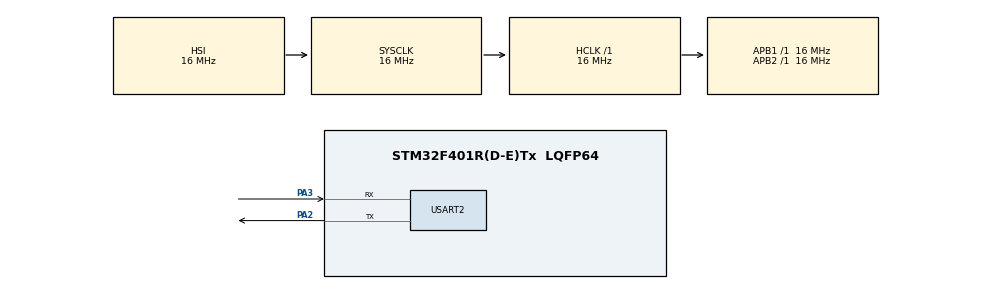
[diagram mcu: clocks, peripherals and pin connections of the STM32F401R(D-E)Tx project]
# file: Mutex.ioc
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FREERTOS.Tasks01=defaultTask,0,128,StartDefaultTask,Default,NULL,Dynamic,NULL,NULL
Mcu.Family=STM32F4
Mcu.Name=STM32F401R(D-E)Tx
Mcu.Package=LQFP64
NVIC.PriorityGroup=NVIC_PRIORITYGROUP_4
NVIC.RCC_IRQn=true\:5\:0\:false\:false\:true\:true\:true\:false\:true
NVIC.TIM1_UP_TIM10_IRQn=true\:15\:0\:false\:false\:true\:false\:false\:true\:true
NVIC.TimeBase=TIM1_UP_TIM10_IRQn
NVIC.TimeBaseIP=TIM1
NVIC.USART2_IRQn=true\:5\:0\:false\:false\:true\:true\:true\:true\:true
PA2.Mode=Asynchronous
PA2.Signal=USART2_TX
PA3.Mode=Asynchronous
PA3.Signal=USART2_RX
PH0\ -\ OSC_IN.Mode=HSE-External-Oscillator
PH0\ -\ OSC_IN.Signal=RCC_OSC_IN
PH1\ -\ OSC_OUT.Mode=HSE-External-Oscillator
PH1\ -\ OSC_OUT.Signal=RCC_OSC_OUT
ProjectManager.HeapSize=0x200
ProjectManager.StackSize=0x400
ProjectManager.TargetToolchain=STM32CubeIDE
RCC.AHBFreq_Value=16000000
RCC.APB1Freq_Value=16000000
RCC.APB2Freq_Value=16000000
RCC.CortexFreq_Value=16000000
RCC.HSE_VALUE=25000000
RCC.HSI_VALUE=16000000
RCC.LSE_VALUE=32768
RCC.SYSCLKFreq_VALUE=16000000
RCC.VCOOutputFreq_Value=192000000
USART2.VirtualMode=VM_ASYNC
VP_FREERTOS_VS_CMSIS_V1.Mode=CMSIS_V1
VP_SYS_VS_tim1.Mode=TIM1
board=custom

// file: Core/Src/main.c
/* USER CODE BEGIN Header */
/**
  ******************************************************************************
  * @file           : main.c
  * @brief          : Main program body
  ******************************************************************************
  * @attention
  *
  * Copyright (c) 2025 STMicroelectronics.
  * All rights reserved.
  *
  * This software is licensed under terms that can be found in the LICENSE file
  * in the root directory of this software component.
  * If no LICENSE file comes with this software, it is provided AS-IS.
  *
  ******************************************************************************
  */
/* USER CODE END Header */
#include "main.h"
#include "cmsis_os.h"

UART_HandleTypeDef huart2;

void SystemClock_Config(void);
static void MX_GPIO_Init(void);
static void MX_USART2_UART_Init(void);

SemaphoreHandle_t SimpleMutex;
TaskHandle_t HPT_Handler;
TaskHandle_t MPT_Handler;
void HPT_Task (void *argument);
void MPT_Task (void *argument);
void Send_Uart (uint8_t *str)
{
xSemaphoreTake(SimpleMutex, portMAX_DELAY);
HAL_Delay(2000);
HAL_UART_Transmit(&huart2, str, strlen (str), HAL_MAX_DELAY);
xSemaphoreGive(SimpleMutex);
}

int main(void)
{

  /* MCU Configuration--------------------------------------------------------*/

  /* Reset of all peripherals, Initializes the Flash interface and the Systick. */
  HAL_Init();

  /* Configure the system clock */
  SystemClock_Config();

  /* Initialize all configured peripherals */
  MX_GPIO_Init();
  MX_USART2_UART_Init();

  /* USER CODE BEGIN RTOS_MUTEX */
  SimpleMutex = xSemaphoreCreateMutex();
  if (SimpleMutex != NULL)
  {
  HAL_UART_Transmit(&huart2, "Mutex Created\n\n", 15, 1000);
  }
  /// create tasks
  xTaskCreate(HPT_Task, "HPT", 128, NULL, 3, &HPT_Handler);
  xTaskCreate(MPT_Task, "MPT", 128, NULL, 2, &MPT_Handler);
  vTaskStartScheduler();
  /* start timers, add new ones, ... */
  /* USER CODE END RTOS_TIMERS */

  /* Start scheduler */
  osKernelStart();

  /* We should never get here as control is now taken by the scheduler */

  /* Infinite loop */
  while (1)
  {

  }
}

void SystemClock_Config(void)
{
  RCC_OscInitTypeDef RCC_OscInitStruct = {0};
  RCC_ClkInitTypeDef RCC_ClkInitStruct = {0};

  /** Configure the main internal regulator output voltage
  */
  __HAL_RCC_PWR_CLK_ENABLE();
  __HAL_PWR_VOLTAGESCALING_CONFIG(PWR_REGULATOR_VOLTAGE_SCALE2);

  /** Initializes the RCC Oscillators according to the specified parameters
  * in the RCC_OscInitTypeDef structure.
  */
  RCC_OscInitStruct.OscillatorType = RCC_OSCILLATORTYPE_HSI;
  RCC_OscInitStruct.HSIState = RCC_HSI_ON;
  RCC_OscInitStruct.HSICalibrationValue = RCC_HSICALIBRATION_DEFAULT;
  RCC_OscInitStruct.PLL.PLLState = RCC_PLL_NONE;
  if (HAL_RCC_OscConfig(&RCC_OscInitStruct) != HAL_OK)
  {
    Error_Handler();
  }

  /** Initializes the CPU, AHB and APB buses clocks
  */
  RCC_ClkInitStruct.ClockType = RCC_CLOCKTYPE_HCLK|RCC_CLOCKTYPE_SYSCLK
                              |RCC_CLOCKTYPE_PCLK1|RCC_CLOCKTYPE_PCLK2;
  RCC_ClkInitStruct.SYSCLKSource = RCC_SYSCLKSOURCE_HSI;
  RCC_ClkInitStruct.AHBCLKDivider = RCC_SYSCLK_DIV1;
  RCC_ClkInitStruct.APB1CLKDivider = RCC_HCLK_DIV1;
  RCC_ClkInitStruct.APB2CLKDivider = RCC_HCLK_DIV1;

  if (HAL_RCC_ClockConfig(&RCC_ClkInitStruct, FLASH_LATENCY_0) != HAL_OK)
  {
    Error_Handler();
  }
}

static void MX_USART2_UART_Init(void)
{

  huart2.Instance = USART2;
  huart2.Init.BaudRate = 115200;
  huart2.Init.WordLength = UART_WORDLENGTH_8B;
  huart2.Init.StopBits = UART_STOPBITS_1;
  huart2.Init.Parity = UART_PARITY_NONE;
  huart2.Init.Mode = UART_MODE_TX_RX;
  huart2.Init.HwFlowCtl = UART_HWCONTROL_NONE;
  huart2.Init.OverSampling = UART_OVERSAMPLING_16;
  if (HAL_UART_Init(&huart2) != HAL_OK)
  {
    Error_Handler();
  }

}

static void MX_GPIO_Init(void)
{

  /* GPIO Ports Clock Enable */
  __HAL_RCC_GPIOH_CLK_ENABLE();
  __HAL_RCC_GPIOA_CLK_ENABLE();

}

/* USER CODE BEGIN 4 */
void HPT_Task (void *argument)
{
uint8_t *strtosend = "IN HPT===========================\n";
while (1)
{
char *str = "Entered HPT and About to take MUTEX\n";
HAL_UART_Transmit(&huart2, str, strlen (str), HAL_MAX_DELAY);
Send_Uart(strtosend);
char *str2 = "Leaving HPT\n\n";
HAL_UART_Transmit(&huart2, str2, strlen (str2), HAL_MAX_DELAY);
vTaskDelay(2000);
}
}
void MPT_Task (void *argument)
{
uint8_t *strtosend = "IN MPT...........................\n";
while (1)
{
char *str = "Entered MPT and About to take MUTEX\n";
HAL_UART_Transmit(&huart2, str, strlen (str), HAL_MAX_DELAY);
Send_Uart(strtosend);
char *str2 = "Leaving MPT\n\n";
HAL_UART_Transmit(&huart2, str2, strlen (str2), HAL_MAX_DELAY);
vTaskDelay(1000);
}
}
/* USER CODE END 4 */

void StartDefaultTask(void const * argument)
{
  for(;;)
  {
    osDelay(1);
  }
}

void HAL_TIM_PeriodElapsedCallback(TIM_HandleTypeDef *htim)
{
  if (htim->Instance == TIM1)
  {
    HAL_IncTick();
  }
}

void Error_Handler(void)
{
  __disable_irq();
  while (1)
  {
  }
}
